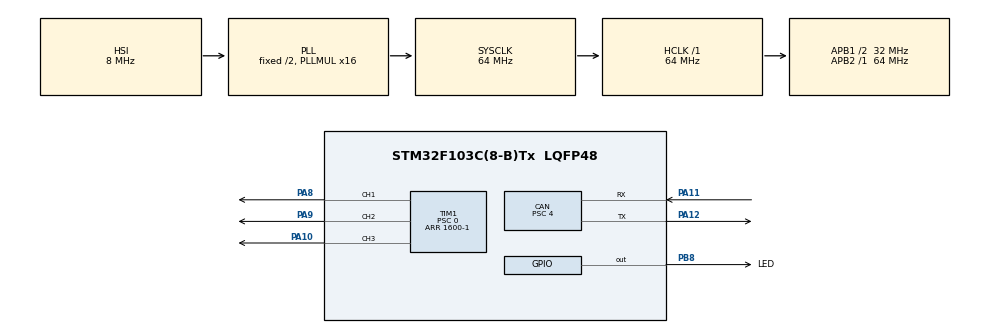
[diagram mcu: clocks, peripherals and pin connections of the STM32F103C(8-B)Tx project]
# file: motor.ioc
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CAN.ABOM=ENABLE
CAN.BS1=CAN_BS1_5TQ
CAN.BS2=CAN_BS2_2TQ
CAN.CalculateBaudRate=1000000
CAN.CalculateTimeBit=1000
CAN.CalculateTimeQuantum=125.0
CAN.Mode=CAN_MODE_NORMAL
CAN.Prescaler=4
CAN.SJW=CAN_SJW_1TQ
Mcu.Family=STM32F1
Mcu.Name=STM32F103C(8-B)Tx
Mcu.Package=LQFP48
NVIC.PriorityGroup=NVIC_PRIORITYGROUP_4
NVIC.TIM1_CC_IRQn=true\:0\:0\:false\:false\:true\:true\:true\:true
NVIC.TIM2_IRQn=true\:1\:0\:true\:false\:true\:true\:true\:true
NVIC.USB_LP_CAN1_RX0_IRQn=true\:0\:0\:false\:false\:true\:true\:true\:true
PA10.Signal=S_TIM1_CH3
PA11.Mode=CAN_Activate
PA11.Signal=CAN_RX
PA12.Mode=CAN_Activate
PA12.Signal=CAN_TX
PA13.Mode=Serial_Wire
PA13.Signal=SYS_JTMS-SWDIO
PA14.Mode=Serial_Wire
PA14.Signal=SYS_JTCK-SWCLK
PA8.Signal=S_TIM1_CH1
PA9.Signal=S_TIM1_CH2
PB8.GPIO_Label=LED
PB8.GPIO_Speed=GPIO_SPEED_FREQ_MEDIUM
PB8.PinState=GPIO_PIN_SET
PB8.Signal=GPIO_Output
ProjectManager.HeapSize=0x200
ProjectManager.StackSize=0x400
ProjectManager.TargetToolchain=CMake
RCC.ADCPresc=RCC_ADCPCLK2_DIV6
RCC.AHBFreq_Value=64000000
RCC.APB1CLKDivider=RCC_HCLK_DIV2
RCC.APB1Freq_Value=32000000
RCC.APB1TimFreq_Value=64000000
RCC.APB2Freq_Value=64000000
RCC.APB2TimFreq_Value=64000000
RCC.HCLKFreq_Value=64000000
RCC.PLLMUL=RCC_PLL_MUL16
RCC.SYSCLKFreq_VALUE=64000000
RCC.SYSCLKSource=RCC_SYSCLKSOURCE_PLLCLK
RCC.USBFreq_Value=64000000
SH.S_TIM1_CH1.0=TIM1_CH1,PWM Generation1 CH1
SH.S_TIM1_CH2.0=TIM1_CH2,PWM Generation2 CH2
SH.S_TIM1_CH3.0=TIM1_CH3,PWM Generation3 CH3
TIM1.AutoReloadPreload=TIM_AUTORELOAD_PRELOAD_ENABLE
TIM1.Channel-Output\ Compare4\ No\ Output=TIM_CHANNEL_4
TIM1.Channel-PWM\ Generation1\ CH1=TIM_CHANNEL_1
TIM1.Channel-PWM\ Generation2\ CH2=TIM_CHANNEL_2
TIM1.Channel-PWM\ Generation3\ CH3=TIM_CHANNEL_3
TIM1.CounterMode=TIM_COUNTERMODE_CENTERALIGNED1
TIM1.OCMode_4=TIM_OCMODE_TIMING
TIM1.Period=1600-1
TIM1.Prescaler=0
TIM1.Pulse-Output\ Compare4\ No\ Output=350-1
TIM1.TIM_MasterOutputTrigger=TIM_TRGO_RESET
TIM1.TIM_MasterSlaveMode=TIM_MASTERSLAVEMODE_DISABLE
TIM2.Period=25-1
TIM2.Prescaler=640-1
VP_TIM1_VS_ClockSourceINT.Mode=Internal
VP_TIM1_VS_no_output4.Mode=Output Compare4 No Output
VP_TIM2_VS_ClockSourceINT.Mode=Internal
board=custom

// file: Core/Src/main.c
/* USER CODE BEGIN Header */
/**
  ******************************************************************************
  * @file           : main.c
  * @brief          : Main program body
  ******************************************************************************
  * @attention
  *
  * Copyright (c) 2025 STMicroelectronics.
  * All rights reserved.
  *
  * This software is licensed under terms that can be found in the LICENSE file
  * in the root directory of this software component.
  * If no LICENSE file comes with this software, it is provided AS-IS.
  *
  ******************************************************************************
  */
/* USER CODE END Header */
#include "main.h"
#include "can.h"
#include "tim.h"
#include "gpio.h"

/* USER CODE BEGIN Includes */
#include <stdio.h>
#include "app/user_main.h"
/* USER CODE END Includes */

void SystemClock_Config(void);

int main(void)
{

  /* MCU Configuration--------------------------------------------------------*/

  /* Reset of all peripherals, Initializes the Flash interface and the Systick. */
  HAL_Init();

  /* Configure the system clock */
  SystemClock_Config();

  /* Initialize all configured peripherals */
  MX_GPIO_Init();
  MX_TIM1_Init();
  MX_TIM2_Init();
  MX_CAN_Init();
  /* USER CODE BEGIN 2 */
  User_Main();
  /* USER CODE END 2 */

  /* Infinite loop */
  /* USER CODE BEGIN WHILE */
  while (1)
  {
//    foc_set_target(0,q_set,0);//功率13.7W电流1.14A

    //定时器触发
    /* USER CODE END WHILE */

  }
}

void SystemClock_Config(void)
{
  RCC_OscInitTypeDef RCC_OscInitStruct = {0};
  RCC_ClkInitTypeDef RCC_ClkInitStruct = {0};

  /** Initializes the RCC Oscillators according to the specified parameters
  * in the RCC_OscInitTypeDef structure.
  */
  RCC_OscInitStruct.OscillatorType = RCC_OSCILLATORTYPE_HSI;
  RCC_OscInitStruct.HSIState = RCC_HSI_ON;
  RCC_OscInitStruct.HSICalibrationValue = RCC_HSICALIBRATION_DEFAULT;
  RCC_OscInitStruct.PLL.PLLState = RCC_PLL_ON;
  RCC_OscInitStruct.PLL.PLLSource = RCC_PLLSOURCE_HSI_DIV2;
  RCC_OscInitStruct.PLL.PLLMUL = RCC_PLL_MUL16;
  if (HAL_RCC_OscConfig(&RCC_OscInitStruct) != HAL_OK)
  {
    Error_Handler();
  }

  /** Initializes the CPU, AHB and APB buses clocks
  */
  RCC_ClkInitStruct.ClockType = RCC_CLOCKTYPE_HCLK|RCC_CLOCKTYPE_SYSCLK
                              |RCC_CLOCKTYPE_PCLK1|RCC_CLOCKTYPE_PCLK2;
  RCC_ClkInitStruct.SYSCLKSource = RCC_SYSCLKSOURCE_PLLCLK;
  RCC_ClkInitStruct.AHBCLKDivider = RCC_SYSCLK_DIV1;
  RCC_ClkInitStruct.APB1CLKDivider = RCC_HCLK_DIV2;
  RCC_ClkInitStruct.APB2CLKDivider = RCC_HCLK_DIV1;

  if (HAL_RCC_ClockConfig(&RCC_ClkInitStruct, FLASH_LATENCY_2) != HAL_OK)
  {
    Error_Handler();
  }
}

void Error_Handler(void)
{
  /* USER CODE BEGIN Error_Handler_Debug */
  /* User can add his own implementation to report the HAL error return state */
  __disable_irq();
  while (1)
  {
      printf("Error Handler");
  }
  /* USER CODE END Error_Handler_Debug */
}
